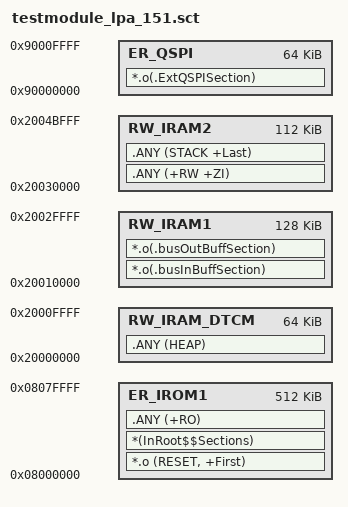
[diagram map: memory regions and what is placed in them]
; *************************************************************
; *** Scatter-Loading Description File generated by uVision ***
; *************************************************************

; internal memory
LR_IROM1 0x08000000 0x00080000 {
    ER_IROM1 0x08000000 0x00080000 {
	*.o (RESET, +First)
	*(InRoot$$Sections)
	.ANY (+RO)
    }

    ; DTCM ram
    RW_IRAM_DTCM 0x20000000 0x00010000 {
	.ANY (HEAP)
    }

    ; SRAM1 (partial)
    RW_IRAM1 0x20010000 0x00020000 {
	*.o(.busInBuffSection)
	*.o(.busOutBuffSection)
    }

    ; SRAM1 (partial) + SRAM2
    RW_IRAM2 0x20030000 0x0001C000 {
	.ANY (+RW +ZI)
	.ANY (STACK +Last)
    }

    ; external sdram 1
    ;RW_ERAM1 0xC0000000 0x10000000 {
	;*.o(.ExtSDRAMSection1)
    ;}

    ; frame buffer 0
    ;RW_FB0 0xD0000000 0x00080000 {
	;*.o(.FrameBuffer0)
    ;}

    ; frame buffer 1
    ;RW_FB1 0xD0080000 0x00080000 {
	;*.o(.FrameBuffer1)
    ;}

    ; external sdram 2
    ;RW_ERAM2 0xD0100000 0x0FF00000 {
	;*.o(.ExtSDRAMSection2)
    ;}
}

; updateable memory area, two last pages
;LR_P1 0x00280000 0x00040000 {
;    ER_P1 0x00280000 FIXED 0x00040000 {
;	*.o (.SelfProgramPage1Section)
;    }
;}
;LR_P2 0x002C0000 0x00040000 {
;    ER_P2 0x002C0000 0x00040000 {
;	*.o (.SelfProgramPage2Section)
;    }
;}

; external flash memory
LR_QSPI 0x90000000 0x00010000 {
    ER_QSPI 0x90000000 0x00010000 {
	*.o(.ExtQSPISection)
    }
}
